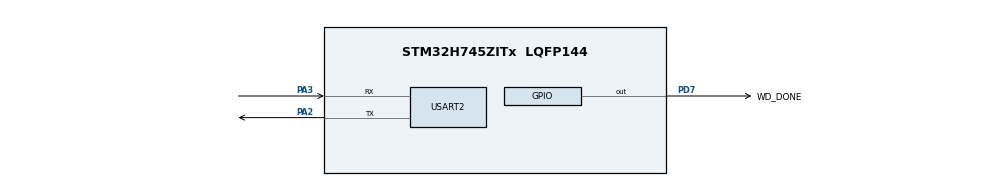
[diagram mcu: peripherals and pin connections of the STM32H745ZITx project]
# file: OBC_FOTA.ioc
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CORTEX_M7.default_mode_Activation=1
CortexM4.IPs=BDMA,CORTEX_M4\:I,DMA,FATFS_M4\:I,FREERTOS_M4\:I,GPIO,IWDG2\:I,MDMA,NVIC2\:I,OPENAMP_M4\:I,PDM2PCM_M4\:I,PWR,RCC,RESMGR_UTILITY,SYS_M4\:I,USB_DEVICE_M4\:I,USB_HOST_M4\:I,VREFBUF,WWDG2\:I,DEBUG
CortexM7.IPs=BDMA\:I,CORTEX_M7\:I,DMA\:I,FATFS_M7\:I,FREERTOS_M7\:I,GPIO\:I,IWDG1\:I,MDMA\:I,NVIC1\:I,OPENAMP_M7\:I,PDM2PCM_M7\:I,PWR\:I,RCC\:I,RESMGR_UTILITY\:I,SYS\:I,USB_DEVICE_M7\:I,USB_HOST_M7\:I,VREFBUF\:I,WWDG1\:I,MEMORYMAP\:I,DEBUG\:I,CRC\:I,USART2\:I
CortexM7.Pins=PD7
Mcu.Family=STM32H7
Mcu.Name=STM32H745ZITx
Mcu.Package=LQFP144
NVIC1.PriorityGroup=NVIC_PRIORITYGROUP_4
NVIC1.USART2_IRQn=true\:0\:0\:false\:false\:true\:true\:true\:true
NVIC2.PriorityGroup=NVIC_PRIORITYGROUP_4
PA13\ (JTMS/SWDIO).Mode=Serial_Wire
PA13\ (JTMS/SWDIO).PinAttribute=CortexM7
PA13\ (JTMS/SWDIO).Signal=DEBUG_JTMS-SWDIO
PA14\ (JTCK/SWCLK).Mode=Serial_Wire
PA14\ (JTCK/SWCLK).PinAttribute=CortexM7
PA14\ (JTCK/SWCLK).Signal=DEBUG_JTCK-SWCLK
PA2.Mode=Asynchronous
PA2.PinAttribute=CortexM7
PA2.Signal=USART2_TX
PA3.Mode=Asynchronous
PA3.PinAttribute=CortexM7
PA3.Signal=USART2_RX
PD7.GPIO_Label=WD_DONE
PD7.PinAttribute=CortexM7
PD7.Signal=GPIO_Output
PH0-OSC_IN\ (PH0).Mode=HSE-External-Oscillator
PH0-OSC_IN\ (PH0).PinAttribute=Free
PH0-OSC_IN\ (PH0).Signal=RCC_OSC_IN
PH1-OSC_OUT\ (PH1).Mode=HSE-External-Oscillator
PH1-OSC_OUT\ (PH1).PinAttribute=Free
PH1-OSC_OUT\ (PH1).Signal=RCC_OSC_OUT
ProjectManager.HeapSize=M4-0x200,M7-0x200
ProjectManager.StackSize=M4-0x400,M7-0x400
ProjectManager.TargetToolchain=STM32CubeIDE
RCC.ADCFreq_Value=129000000
RCC.APB1Freq_Value=24000000
RCC.APB2Freq_Value=12000000
RCC.APB3Freq_Value=24000000
RCC.APB4Freq_Value=24000000
RCC.CortexFreq_Value=48000000
RCC.D1CPRE=RCC_SYSCLK_DIV2
RCC.D2PPRE2=RCC_APB2_DIV2
RCC.DIVM1=4
RCC.DIVN1=12
RCC.HCLKFreq_Value=24000000
RCC.HPRE=RCC_HCLK_DIV2
RCC.PLL2FRACN=0
RCC.PLL3FRACN=0
RCC.PLLFRACN=0
RCC.SYSCLKFreq_VALUE=96000000
RCC.SYSCLKSource=RCC_SYSCLKSOURCE_PLLCLK
RCC.SupplySource=PWR_LDO_SUPPLY
RCC.USBFreq_Value=96000000
SYS.userName=SYS_M7
USART2.VirtualMode-Asynchronous=VM_ASYNC
VP_CRC_VS_CRC.Mode=CRC_Activate
VP_MEMORYMAP_VS_MEMORYMAP.Mode=CurAppReg
VP_SYS_M4_VS_Systick.Mode=SysTick
board=custom

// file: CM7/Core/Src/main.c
/* USER CODE BEGIN Header */
/**
  ******************************************************************************
  * @file           : main.c
  * @brief          : Main program body
  ******************************************************************************
  * @attention
  *
  * Copyright (c) 2025 STMicroelectronics.
  * All rights reserved.
  *
  * This software is licensed under terms that can be found in the LICENSE file
  * in the root directory of this software component.
  * If no LICENSE file comes with this software, it is provided AS-IS.
  *
  ******************************************************************************
  */
/* USER CODE END Header */
#include "main.h"

/* USER CODE BEGIN Includes */
#include "UART.h"
#include "bootloader.h"
#include "scheduler.h"
/* USER CODE END Includes */

CRC_HandleTypeDef hcrc;

void SystemClock_Config(void);
static void MPU_Config(void);
static void MX_GPIO_Init(void);
static void MX_CRC_Init(void);
static void MX_USART2_UART_Init(void);

/* USER CODE BEGIN 0 */
static void watchdog_handler(void*);

#define         SCHEDULER_TASK_COUNT  3
uint32_t g_ui32SchedulerNumTasks = SCHEDULER_TASK_COUNT;
tSchedulerTask g_psSchedulerTable[SCHEDULER_TASK_COUNT] =
{
    {
        .pfnFunction = watchdog_handler,     		// Hàm xử lí watchdog
        .pvParam = (void*)0,                 		// Không có tham số
        .ui32FrequencyTicks = 500,           		// Gọi mỗi 500ms (500 tick, giả sử 1 tick = 1ms)
        .ui32LastCall = 0,                   		// Khởi tạo thời điểm gọi lần cuối
		.bActive = true                      		// Kích hoạt
    },
    {
        .pfnFunction = BL_UART_Fetch_Host_Command, 	// Hàm xử lý lệnh UART
        .pvParam = (void*)0,                 		// Không có tham số
        .ui32FrequencyTicks = 10,             		// Gọi mỗi 10ms (10 tick, giả sử 1 tick = 1ms)
        .ui32LastCall = 0,                   		// Khởi tạo thời điểm gọi lần cuối
        .bActive = true                      		// Kích hoạt
    },
    {
        .pfnFunction = Bootloader_Check_Timeout, 	// Hàm xử lý lệnh UART
        .pvParam = (void*)0,                 		// Không có tham số
        .ui32FrequencyTicks = 10,             		// Gọi mỗi 10ms (10 tick, giả sử 1 tick = 1ms)
        .ui32LastCall = 0,                   		// Khởi tạo thời điểm gọi lần cuối
        .bActive = true                      		// Kích hoạt
    }
};

static void watchdog_handler(void*)
{
	HAL_GPIO_TogglePin(WD_DONE_GPIO_Port, WD_DONE_Pin);
}

/* USER CODE END 0 */

int main(void)
{

/* USER CODE BEGIN Boot_Mode_Sequence_0 */

/* USER CODE END Boot_Mode_Sequence_0 */

  /* MPU Configuration--------------------------------------------------------*/
  MPU_Config();

/* USER CODE BEGIN Boot_Mode_Sequence_1 */

/* USER CODE END Boot_Mode_Sequence_1 */
  /* MCU Configuration--------------------------------------------------------*/

  /* Reset of all peripherals, Initializes the Flash interface and the Systick. */
  HAL_Init();

  /* Configure the system clock */
  SystemClock_Config();
/* USER CODE BEGIN Boot_Mode_Sequence_2 */

/* USER CODE END Boot_Mode_Sequence_2 */

  /* Initialize all configured peripherals */
  MX_GPIO_Init();
  MX_CRC_Init();
  MX_USART2_UART_Init();
  /* USER CODE BEGIN 2 */
  SchedulerInit(1000);
  USART2_init();
  validate_no_init_vars();
  /* USER CODE END 2 */

  /* Infinite loop */
  while (1)
  {

    /* USER CODE BEGIN 3 */
	  SchedulerRun();
  }
  /* USER CODE END 3 */
}

void SystemClock_Config(void)
{
  RCC_OscInitTypeDef RCC_OscInitStruct = {0};
  RCC_ClkInitTypeDef RCC_ClkInitStruct = {0};

  /** Supply configuration update enable
  */
  HAL_PWREx_ConfigSupply(PWR_LDO_SUPPLY);

  /** Configure the main internal regulator output voltage
  */
  __HAL_PWR_VOLTAGESCALING_CONFIG(PWR_REGULATOR_VOLTAGE_SCALE3);

  while(!__HAL_PWR_GET_FLAG(PWR_FLAG_VOSRDY)) {}

  /** Initializes the RCC Oscillators according to the specified parameters
  * in the RCC_OscInitTypeDef structure.
  */
  RCC_OscInitStruct.OscillatorType = RCC_OSCILLATORTYPE_HSI;
  RCC_OscInitStruct.HSIState = RCC_HSI_DIV1;
  RCC_OscInitStruct.HSICalibrationValue = RCC_HSICALIBRATION_DEFAULT;
  RCC_OscInitStruct.PLL.PLLState = RCC_PLL_ON;
  RCC_OscInitStruct.PLL.PLLSource = RCC_PLLSOURCE_HSI;
  RCC_OscInitStruct.PLL.PLLM = 4;
  RCC_OscInitStruct.PLL.PLLN = 12;
  RCC_OscInitStruct.PLL.PLLP = 2;
  RCC_OscInitStruct.PLL.PLLQ = 2;
  RCC_OscInitStruct.PLL.PLLR = 2;
  RCC_OscInitStruct.PLL.PLLRGE = RCC_PLL1VCIRANGE_3;
  RCC_OscInitStruct.PLL.PLLVCOSEL = RCC_PLL1VCOWIDE;
  RCC_OscInitStruct.PLL.PLLFRACN = 0;
  if (HAL_RCC_OscConfig(&RCC_OscInitStruct) != HAL_OK)
  {
    Error_Handler();
  }

  /** Initializes the CPU, AHB and APB buses clocks
  */
  RCC_ClkInitStruct.ClockType = RCC_CLOCKTYPE_HCLK|RCC_CLOCKTYPE_SYSCLK
                              |RCC_CLOCKTYPE_PCLK1|RCC_CLOCKTYPE_PCLK2
                              |RCC_CLOCKTYPE_D3PCLK1|RCC_CLOCKTYPE_D1PCLK1;
  RCC_ClkInitStruct.SYSCLKSource = RCC_SYSCLKSOURCE_PLLCLK;
  RCC_ClkInitStruct.SYSCLKDivider = RCC_SYSCLK_DIV2;
  RCC_ClkInitStruct.AHBCLKDivider = RCC_HCLK_DIV2;
  RCC_ClkInitStruct.APB3CLKDivider = RCC_APB3_DIV1;
  RCC_ClkInitStruct.APB1CLKDivider = RCC_APB1_DIV1;
  RCC_ClkInitStruct.APB2CLKDivider = RCC_APB2_DIV2;
  RCC_ClkInitStruct.APB4CLKDivider = RCC_APB4_DIV1;

  if (HAL_RCC_ClockConfig(&RCC_ClkInitStruct, FLASH_LATENCY_0) != HAL_OK)
  {
    Error_Handler();
  }
}

static void MX_CRC_Init(void)
{

  hcrc.Instance = CRC;
  hcrc.Init.DefaultPolynomialUse = DEFAULT_POLYNOMIAL_ENABLE;
  hcrc.Init.DefaultInitValueUse = DEFAULT_INIT_VALUE_ENABLE;
  hcrc.Init.InputDataInversionMode = CRC_INPUTDATA_INVERSION_NONE;
  hcrc.Init.OutputDataInversionMode = CRC_OUTPUTDATA_INVERSION_DISABLE;
  hcrc.InputDataFormat = CRC_INPUTDATA_FORMAT_BYTES;
  if (HAL_CRC_Init(&hcrc) != HAL_OK)
  {
    Error_Handler();
  }

}

static void MX_USART2_UART_Init(void)
{

  LL_USART_InitTypeDef USART_InitStruct = {0};

  LL_GPIO_InitTypeDef GPIO_InitStruct = {0};
  RCC_PeriphCLKInitTypeDef PeriphClkInitStruct = {0};

  /** Initializes the peripherals clock
  */
  PeriphClkInitStruct.PeriphClockSelection = RCC_PERIPHCLK_USART2;
  PeriphClkInitStruct.Usart234578ClockSelection = RCC_USART234578CLKSOURCE_D2PCLK1;
  if (HAL_RCCEx_PeriphCLKConfig(&PeriphClkInitStruct) != HAL_OK)
  {
    Error_Handler();
  }

  /* Peripheral clock enable */
  LL_APB1_GRP1_EnableClock(LL_APB1_GRP1_PERIPH_USART2);

  LL_AHB4_GRP1_EnableClock(LL_AHB4_GRP1_PERIPH_GPIOA);
  /**USART2 GPIO Configuration
  PA2   ------> USART2_TX
  PA3   ------> USART2_RX
  */
  GPIO_InitStruct.Pin = LL_GPIO_PIN_2|LL_GPIO_PIN_3;
  GPIO_InitStruct.Mode = LL_GPIO_MODE_ALTERNATE;
  GPIO_InitStruct.Speed = LL_GPIO_SPEED_FREQ_LOW;
  GPIO_InitStruct.OutputType = LL_GPIO_OUTPUT_PUSHPULL;
  GPIO_InitStruct.Pull = LL_GPIO_PULL_NO;
  GPIO_InitStruct.Alternate = LL_GPIO_AF_7;
  LL_GPIO_Init(GPIOA, &GPIO_InitStruct);

  /* USART2 interrupt Init */
  NVIC_SetPriority(USART2_IRQn, NVIC_EncodePriority(NVIC_GetPriorityGrouping(),0, 0));
  NVIC_EnableIRQ(USART2_IRQn);

  USART_InitStruct.PrescalerValue = LL_USART_PRESCALER_DIV1;
  USART_InitStruct.BaudRate = 115200;
  USART_InitStruct.DataWidth = LL_USART_DATAWIDTH_8B;
  USART_InitStruct.StopBits = LL_USART_STOPBITS_1;
  USART_InitStruct.Parity = LL_USART_PARITY_NONE;
  USART_InitStruct.TransferDirection = LL_USART_DIRECTION_TX_RX;
  USART_InitStruct.HardwareFlowControl = LL_USART_HWCONTROL_NONE;
  USART_InitStruct.OverSampling = LL_USART_OVERSAMPLING_16;
  LL_USART_Init(USART2, &USART_InitStruct);
  LL_USART_SetTXFIFOThreshold(USART2, LL_USART_FIFOTHRESHOLD_1_8);
  LL_USART_SetRXFIFOThreshold(USART2, LL_USART_FIFOTHRESHOLD_1_8);
  LL_USART_DisableFIFO(USART2);
  LL_USART_ConfigAsyncMode(USART2);

  LL_USART_Enable(USART2);

  /* Polling USART2 initialisation */
  while((!(LL_USART_IsActiveFlag_TEACK(USART2))) || (!(LL_USART_IsActiveFlag_REACK(USART2))))
  {
  }

}

static void MX_GPIO_Init(void)
{
  GPIO_InitTypeDef GPIO_InitStruct = {0};

  /* GPIO Ports Clock Enable */
  __HAL_RCC_GPIOA_CLK_ENABLE();
  __HAL_RCC_GPIOD_CLK_ENABLE();

  /*Configure GPIO pin Output Level */
  HAL_GPIO_WritePin(WD_DONE_GPIO_Port, WD_DONE_Pin, GPIO_PIN_RESET);

  /*Configure GPIO pin : WD_DONE_Pin */
  GPIO_InitStruct.Pin = WD_DONE_Pin;
  GPIO_InitStruct.Mode = GPIO_MODE_OUTPUT_PP;
  GPIO_InitStruct.Pull = GPIO_NOPULL;
  GPIO_InitStruct.Speed = GPIO_SPEED_FREQ_LOW;
  HAL_GPIO_Init(WD_DONE_GPIO_Port, &GPIO_InitStruct);

}

 /* MPU Configuration */

void MPU_Config(void)
{
  MPU_Region_InitTypeDef MPU_InitStruct = {0};

  /* Disables the MPU */
  HAL_MPU_Disable();

  /** Initializes and configures the Region and the memory to be protected
  */
  MPU_InitStruct.Enable = MPU_REGION_ENABLE;
  MPU_InitStruct.Number = MPU_REGION_NUMBER0;
  MPU_InitStruct.BaseAddress = 0x0;
  MPU_InitStruct.Size = MPU_REGION_SIZE_4GB;
  MPU_InitStruct.SubRegionDisable = 0x87;
  MPU_InitStruct.TypeExtField = MPU_TEX_LEVEL0;
  MPU_InitStruct.AccessPermission = MPU_REGION_NO_ACCESS;
  MPU_InitStruct.DisableExec = MPU_INSTRUCTION_ACCESS_DISABLE;
  MPU_InitStruct.IsShareable = MPU_ACCESS_SHAREABLE;
  MPU_InitStruct.IsCacheable = MPU_ACCESS_NOT_CACHEABLE;
  MPU_InitStruct.IsBufferable = MPU_ACCESS_NOT_BUFFERABLE;

  HAL_MPU_ConfigRegion(&MPU_InitStruct);
  /* Enables the MPU */
  HAL_MPU_Enable(MPU_PRIVILEGED_DEFAULT);

}

void Error_Handler(void)
{
  __disable_irq();
  while (1)
  {
  }
}
